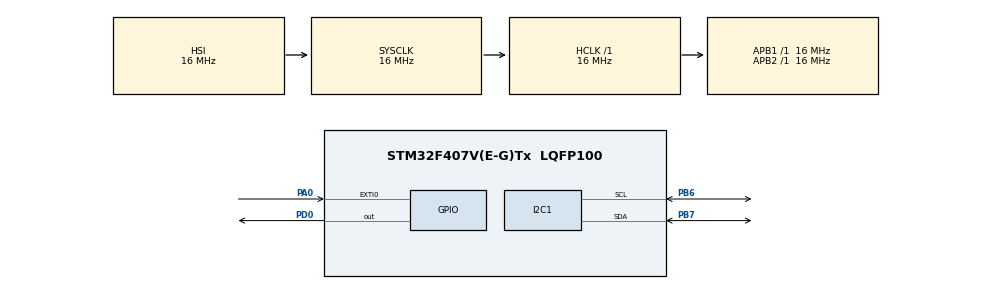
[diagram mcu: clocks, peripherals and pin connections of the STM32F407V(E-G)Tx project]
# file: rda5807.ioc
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I2C1.I2C_Mode=I2C_Fast
Mcu.Family=STM32F4
Mcu.Name=STM32F407V(E-G)Tx
Mcu.Package=LQFP100
NVIC.EXTI0_IRQn=true\:0\:0\:false\:false\:true
NVIC.PriorityGroup=NVIC_PRIORITYGROUP_4
NVIC.TIM6_DAC_IRQn=true\:0\:0\:false\:false\:true
PA0-WKUP.GPIO_PuPd=GPIO_NOPULL
PA0-WKUP.Signal=GPXTI0
PA13.Mode=Serial_Wire
PA13.Signal=SYS_JTMS-SWDIO
PA14.Mode=Serial_Wire
PA14.Signal=SYS_JTCK-SWCLK
PB6.Mode=I2C
PB6.Signal=I2C1_SCL
PB7.Mode=I2C
PB7.Signal=I2C1_SDA
PD0.Signal=GPIO_Output
PH0-OSC_IN.Mode=HSE-External-Oscillator
PH0-OSC_IN.Signal=RCC_OSC_IN
PH1-OSC_OUT.Mode=HSE-External-Oscillator
PH1-OSC_OUT.Signal=RCC_OSC_OUT
ProjectManager.HeapSize=0x1000
ProjectManager.StackSize=0x2000
ProjectManager.TargetToolchain=MDK-ARM V5
RCC.48MHZClocksFreq_Value=48000000
RCC.AHBFreq_Value=16000000
RCC.APB1Freq_Value=16000000
RCC.APB2Freq_Value=16000000
RCC.CortexFreq_Value=16000000
RCC.HSE_VALUE=8000000
RCC.HSI_VALUE=16000000
RCC.LSE_VALUE=32768
RCC.PLLM=4
RCC.PLLN=72
RCC.PLLQ=3
RCC.PLLSourceVirtual=RCC_PLLSOURCE_HSE
RCC.SYSCLKFreq_VALUE=16000000
RCC.VCOOutputFreq_Value=144000000
TIM6.Period=100
TIM6.Prescaler=16
VP_TIM6_VS_ClockSourceINT.Mode=Enable_Timer
board=rda5807

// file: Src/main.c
/**
  ******************************************************************************
  * File Name          : main.c
  * Description        : Main program body
  ******************************************************************************
  ** This notice applies to any and all portions of this file
  * that are not between comment pairs USER CODE BEGIN and
  * USER CODE END. Other portions of this file, whether
  * inserted by the user or by software development tools
  * are owned by their respective copyright owners.
  *
  * COPYRIGHT(c) 2017 STMicroelectronics
  *
  * Redistribution and use in source and binary forms, with or without modification,
  * are permitted provided that the following conditions are met:
  *   1. Redistributions of source code must retain the above copyright notice,
  *      this list of conditions and the following disclaimer.
  *   2. Redistributions in binary form must reproduce the above copyright notice,
  *      this list of conditions and the following disclaimer in the documentation
  *      and/or other materials provided with the distribution.
  *   3. Neither the name of STMicroelectronics nor the names of its contributors
  *      may be used to endorse or promote products derived from this software
  *      without specific prior written permission.
  *
  * THIS SOFTWARE IS PROVIDED BY THE COPYRIGHT HOLDERS AND CONTRIBUTORS "AS IS"
  * AND ANY EXPRESS OR IMPLIED WARRANTIES, INCLUDING, BUT NOT LIMITED TO, THE
  * IMPLIED WARRANTIES OF MERCHANTABILITY AND FITNESS FOR A PARTICULAR PURPOSE ARE
  * DISCLAIMED. IN NO EVENT SHALL THE COPYRIGHT HOLDER OR CONTRIBUTORS BE LIABLE
  * FOR ANY DIRECT, INDIRECT, INCIDENTAL, SPECIAL, EXEMPLARY, OR CONSEQUENTIAL
  * DAMAGES (INCLUDING, BUT NOT LIMITED TO, PROCUREMENT OF SUBSTITUTE GOODS OR
  * SERVICES; LOSS OF USE, DATA, OR PROFITS; OR BUSINESS INTERRUPTION) HOWEVER
  * CAUSED AND ON ANY THEORY OF LIABILITY, WHETHER IN CONTRACT, STRICT LIABILITY,
  * OR TORT (INCLUDING NEGLIGENCE OR OTHERWISE) ARISING IN ANY WAY OUT OF THE USE
  * OF THIS SOFTWARE, EVEN IF ADVISED OF THE POSSIBILITY OF SUCH DAMAGE.
  *
  ******************************************************************************
  */
#include "main.h"
#include "stm32f4xx_hal.h"

/* USER CODE BEGIN Includes */

#include "rda5807m.h"
#include <string.h>

/* USER CODE END Includes */

I2C_HandleTypeDef hi2c1;

TIM_HandleTypeDef htim6;

/* USER CODE BEGIN PV */
/* Private variables ---------------------------------------------------------*/

unsigned char MsgBuff[256];
uint16_t Chan=0;
uint16_t RSSI=0;
float Freq;

/* USER CODE END PV */

void SystemClock_Config(void);
static void MX_GPIO_Init(void);
static void MX_I2C1_Init(void);
static void MX_TIM6_Init(void);

/* USER CODE BEGIN PFP */
/* Private function prototypes -----------------------------------------------*/

/* USER CODE END PFP */

int main(void)
{

  /* MCU Configuration----------------------------------------------------------*/

  /* Reset of all peripherals, Initializes the Flash interface and the Systick. */
  HAL_Init();

  /* Configure the system clock */
  SystemClock_Config();

  /* Initialize all configured peripherals */
  MX_GPIO_Init();
  MX_I2C1_Init();
  MX_TIM6_Init();

  /* USER CODE BEGIN 2 */

		HAL_TIM_Base_Start_IT(&htim6);

	  RDA5807m_Init();
		HAL_Delay(1000);

		RDA5807m_SetBand(BAND_76_108);
		RDA5807m_SetStep(STEP_100);
		//RDA5807m_SetFreq(96.7);

		//HAL_Delay(1000);

  /* USER CODE END 2 */

  /* Infinite loop */
  /* USER CODE BEGIN WHILE */
  while (1)
  {
		Chan=RDA5807m_GetChan();
		RSSI=RDA5807m_GetRSSI();
		Freq=RDA5807m_GetFreq();
  /* USER CODE END WHILE */

  }

}

/** System Clock Configuration
*/
void SystemClock_Config(void)
{

  RCC_OscInitTypeDef RCC_OscInitStruct;
  RCC_ClkInitTypeDef RCC_ClkInitStruct;

    /**Configure the main internal regulator output voltage
    */
  __HAL_RCC_PWR_CLK_ENABLE();

  __HAL_PWR_VOLTAGESCALING_CONFIG(PWR_REGULATOR_VOLTAGE_SCALE1);

    /**Initializes the CPU, AHB and APB busses clocks
    */
  RCC_OscInitStruct.OscillatorType = RCC_OSCILLATORTYPE_HSI;
  RCC_OscInitStruct.HSIState = RCC_HSI_ON;
  RCC_OscInitStruct.HSICalibrationValue = 16;
  RCC_OscInitStruct.PLL.PLLState = RCC_PLL_NONE;
  if (HAL_RCC_OscConfig(&RCC_OscInitStruct) != HAL_OK)
  {
    _Error_Handler(__FILE__, __LINE__);
  }

    /**Initializes the CPU, AHB and APB busses clocks
    */
  RCC_ClkInitStruct.ClockType = RCC_CLOCKTYPE_HCLK|RCC_CLOCKTYPE_SYSCLK
                              |RCC_CLOCKTYPE_PCLK1|RCC_CLOCKTYPE_PCLK2;
  RCC_ClkInitStruct.SYSCLKSource = RCC_SYSCLKSOURCE_HSI;
  RCC_ClkInitStruct.AHBCLKDivider = RCC_SYSCLK_DIV1;
  RCC_ClkInitStruct.APB1CLKDivider = RCC_HCLK_DIV1;
  RCC_ClkInitStruct.APB2CLKDivider = RCC_HCLK_DIV1;

  if (HAL_RCC_ClockConfig(&RCC_ClkInitStruct, FLASH_LATENCY_0) != HAL_OK)
  {
    _Error_Handler(__FILE__, __LINE__);
  }

    /**Configure the Systick interrupt time
    */
  HAL_SYSTICK_Config(HAL_RCC_GetHCLKFreq()/1000);

    /**Configure the Systick
    */
  HAL_SYSTICK_CLKSourceConfig(SYSTICK_CLKSOURCE_HCLK);

  /* SysTick_IRQn interrupt configuration */
  HAL_NVIC_SetPriority(SysTick_IRQn, 0, 0);
}

/* I2C1 init function */
static void MX_I2C1_Init(void)
{

  hi2c1.Instance = I2C1;
  hi2c1.Init.ClockSpeed = 400000;
  hi2c1.Init.DutyCycle = I2C_DUTYCYCLE_2;
  hi2c1.Init.OwnAddress1 = 0;
  hi2c1.Init.AddressingMode = I2C_ADDRESSINGMODE_7BIT;
  hi2c1.Init.DualAddressMode = I2C_DUALADDRESS_DISABLE;
  hi2c1.Init.OwnAddress2 = 0;
  hi2c1.Init.GeneralCallMode = I2C_GENERALCALL_DISABLE;
  hi2c1.Init.NoStretchMode = I2C_NOSTRETCH_DISABLE;
  if (HAL_I2C_Init(&hi2c1) != HAL_OK)
  {
    _Error_Handler(__FILE__, __LINE__);
  }

}

/* TIM6 init function */
static void MX_TIM6_Init(void)
{

  TIM_MasterConfigTypeDef sMasterConfig;

  htim6.Instance = TIM6;
  htim6.Init.Prescaler = 16;
  htim6.Init.CounterMode = TIM_COUNTERMODE_UP;
  htim6.Init.Period = 100;
  if (HAL_TIM_Base_Init(&htim6) != HAL_OK)
  {
    _Error_Handler(__FILE__, __LINE__);
  }

  sMasterConfig.MasterOutputTrigger = TIM_TRGO_RESET;
  sMasterConfig.MasterSlaveMode = TIM_MASTERSLAVEMODE_DISABLE;
  if (HAL_TIMEx_MasterConfigSynchronization(&htim6, &sMasterConfig) != HAL_OK)
  {
    _Error_Handler(__FILE__, __LINE__);
  }

}

/** Configure pins as
        * Analog
        * Input
        * Output
        * EVENT_OUT
        * EXTI
*/
static void MX_GPIO_Init(void)
{

  GPIO_InitTypeDef GPIO_InitStruct;

  /* GPIO Ports Clock Enable */
  __HAL_RCC_GPIOH_CLK_ENABLE();
  __HAL_RCC_GPIOA_CLK_ENABLE();
  __HAL_RCC_GPIOD_CLK_ENABLE();
  __HAL_RCC_GPIOB_CLK_ENABLE();

  /*Configure GPIO pin Output Level */
  HAL_GPIO_WritePin(GPIOD, GPIO_PIN_0, GPIO_PIN_RESET);

  /*Configure GPIO pin : PA0 */
  GPIO_InitStruct.Pin = GPIO_PIN_0;
  GPIO_InitStruct.Mode = GPIO_MODE_IT_RISING;
  GPIO_InitStruct.Pull = GPIO_NOPULL;
  HAL_GPIO_Init(GPIOA, &GPIO_InitStruct);

  /*Configure GPIO pin : PD0 */
  GPIO_InitStruct.Pin = GPIO_PIN_0;
  GPIO_InitStruct.Mode = GPIO_MODE_OUTPUT_PP;
  GPIO_InitStruct.Pull = GPIO_NOPULL;
  GPIO_InitStruct.Speed = GPIO_SPEED_FREQ_LOW;
  HAL_GPIO_Init(GPIOD, &GPIO_InitStruct);

  /* EXTI interrupt init*/
  HAL_NVIC_SetPriority(EXTI0_IRQn, 0, 0);
  HAL_NVIC_EnableIRQ(EXTI0_IRQn);

}

void _Error_Handler(char * file, int line)
{
  while(1)
  {
  }
}

/************************ (C) COPYRIGHT STMicroelectronics *****END OF FILE****/
